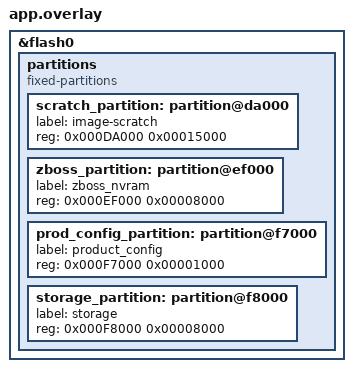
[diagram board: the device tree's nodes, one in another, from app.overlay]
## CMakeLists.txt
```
#
# Copyright (c) 2020 Nordic Semiconductor ASA
#
# SPDX-License-Identifier: LicenseRef-Nordic-5-Clause
#

cmake_minimum_required(VERSION 3.20.0)

find_package(Zephyr REQUIRED HINTS $ENV{ZEPHYR_BASE})

project("Light Switch")

# NORDIC SDK APP START
target_sources(app PRIVATE
  src/main.c
)

target_include_directories(app PRIVATE include)
# NORDIC SDK APP END

target_sources_ifdef(CONFIG_BT_NUS app PRIVATE
  src/nus_cmd.c
)
```

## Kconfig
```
#
# Copyright (c) 2020 Nordic Semiconductor ASA
#
# SPDX-License-Identifier: LicenseRef-Nordic-5-Clause
#

menu "Zephyr Kernel"
source "Kconfig.zephyr"
endmenu

module = NUS_CMD
module-str = NUS command
source "${ZEPHYR_BASE}/subsys/logging/Kconfig.template.log_config"


config LIGHT_SWITCH_CONFIGURE_TX_POWER
	bool "Configure TX power"
	default y
	help
		Enable this option to configure TX power for the sample.

config LIGHT_SWITCH_TX_POWER
	int "TX power"
	depends on LIGHT_SWITCH_CONFIGURE_TX_POWER
	default 0
	help
		TX power level in dBm.
```

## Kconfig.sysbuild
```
#
# Copyright (c) 2023 Nordic Semiconductor
#
# SPDX-License-Identifier: LicenseRef-Nordic-5-Clause
#

#### Radio core selection
config NRF_DEFAULT_IPC_RADIO
	default y

if BOOTLOADER_MCUBOOT

#### DFU multi-image support
config DFU_MULTI_IMAGE_PACKAGE_BUILD
	default y

config DFU_MULTI_IMAGE_PACKAGE_APP
	default y

#### DFU dual core configuration
if SOC_SERIES_NRF53X

config PM_EXTERNAL_FLASH_MCUBOOT_SECONDARY
	default y

config MCUBOOT_UPDATEABLE_IMAGES
	default 2

choice MCUBOOT_MODE
	default MCUBOOT_MODE_OVERWRITE_ONLY
endchoice

config SECURE_BOOT_NETCORE
	default y

config NETCORE_APP_UPDATE
	default y

config DFU_MULTI_IMAGE_PACKAGE_NET
	default y

endif # SOC_SERIES_NRF53X

endif # BOOTLOADER_MCUBOOT

source "share/sysbuild/Kconfig"
```

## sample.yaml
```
sample:
  description: Zigbee dimmable light switch based on ZBOSS stack
  name: Zigbee Light switch
tests:
  sample.zigbee.light_switch:
    sysbuild: true
    build_only: true
    integration_platforms:
      - nrf52840dk/nrf52840
      - nrf52833dk/nrf52833
      - nrf5340dk/nrf5340/cpuapp
      - nrf21540dk/nrf52840
    platform_allow:
      - nrf52840dk/nrf52840
      - nrf52833dk/nrf52833
      - nrf5340dk/nrf5340/cpuapp
      - nrf21540dk/nrf52840
    tags:
      - ci_build
      - smoke
      - sysbuild
      - ci_samples_zigbee
  sample.zigbee.light_switch.current_measurement:
    sysbuild: true
    build_only: true
    extra_args: CONFIG_SERIAL=n
    integration_platforms:
      - nrf52840dk/nrf52840
      - nrf52833dk/nrf52833
      - nrf5340dk/nrf5340/cpuapp
    platform_allow:
      - nrf52840dk/nrf52840
      - nrf52833dk/nrf52833
      - nrf5340dk/nrf5340/cpuapp
    tags:
      - ci_build
      - current_measurement
      - sysbuild
      - ci_samples_zigbee
  sample.zigbee.light_switch.fota:
    sysbuild: true
    build_only: true
    extra_args: >
      FILE_SUFFIX=fota
    integration_platforms:
      - nrf52840dk/nrf52840
      - nrf21540dk/nrf52840
    platform_allow:
      - nrf52840dk/nrf52840
      - nrf21540dk/nrf52840
    tags:
      - ci_build
      - smoke
      - sysbuild
      - ci_samples_zigbee
  sample.zigbee.light_switch.fota.nrf5340dk:
    sysbuild: true
    build_only: true
    extra_args: >
      FILE_SUFFIX=fota
    integration_platforms:
      - nrf5340dk/nrf5340/cpuapp
    platform_allow: nrf5340dk/nrf5340/cpuapp
    tags:
      - ci_build
      - smoke
      - sysbuild
      - ci_samples_zigbee
  sample.zigbee.light_switch.fota_and_multiprotocol:
    sysbuild: true
    build_only: true
    extra_args:
      - FILE_SUFFIX=fota
      - OVERLAY_CONFIG=overlay-multiprotocol_ble.conf
    integration_platforms:
      - nrf52840dk/nrf52840
    platform_allow: nrf52840dk/nrf52840
    tags:
      - ci_build
      - sysbuild
      - ci_samples_zigbee
  sample.zigbee.light_switch.fota_and_multiprotocol.nrf5340dk:
    sysbuild: true
    build_only: true
    extra_args:
      - FILE_SUFFIX=fota
      - OVERLAY_CONFIG=overlay-multiprotocol_ble.conf
    integration_platforms:
      - nrf5340dk/nrf5340/cpuapp
    platform_allow: nrf5340dk/nrf5340/cpuapp
    tags:
      - ci_build
      - sysbuild
      - ci_samples_zigbee
  sample.zigbee.light_switch.multiprotocol:
    sysbuild: true
    build_only: true
    extra_args: OVERLAY_CONFIG=overlay-multiprotocol_ble.conf
    integration_platforms:
      - nrf52840dk/nrf52840
      - nrf52833dk/nrf52833
      - nrf5340dk/nrf5340/cpuapp
    platform_allow:
      - nrf52840dk/nrf52840
      - nrf52833dk/nrf52833
      - nrf5340dk/nrf5340/cpuapp
    tags:
      - ci_build
      - sysbuild
      - ci_samples_zigbee
  sample.zigbee.light_switch.with_shell:
    sysbuild: true
    build_only: true
    extra_args:
      - CONFIG_ZIGBEE_SHELL=y
      - CONFIG_ZIGBEE_SHELL_DEBUG_CMD=y
      - CONFIG_ZIGBEE_LOGGER_EP=n
      - CONFIG_ZIGBEE_SHELL_ENDPOINT=1
      - CONFIG_LOG_MODE_DEFERRED=y
    integration_platforms:
      - nrf52840dk/nrf52840
      - nrf52833dk/nrf52833
      - nrf5340dk/nrf5340/cpuapp
      - nrf21540dk/nrf52840
    platform_allow:
      - nrf52840dk/nrf52840
      - nrf52833dk/nrf52833
      - nrf5340dk/nrf5340/cpuapp
      - nrf21540dk/nrf52840
    tags:
      - ci_build
      - shell
      - sysbuild
      - ci_samples_zigbee
```

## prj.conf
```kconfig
#
# Copyright (c) 2020 Nordic Semiconductor ASA
#
# SPDX-License-Identifier: LicenseRef-Nordic-5-Clause
#

CONFIG_NCS_SAMPLES_DEFAULTS=y

CONFIG_UART_INTERRUPT_DRIVEN=y
CONFIG_SERIAL=y
CONFIG_GPIO=y

# Make sure printk is not printing to the UART console
CONFIG_CONSOLE=y
CONFIG_UART_CONSOLE=y

CONFIG_HEAP_MEM_POOL_SIZE=2048

CONFIG_ZIGBEE=y
CONFIG_ZIGBEE_APP_UTILS=y
CONFIG_ZIGBEE_ROLE_END_DEVICE=y

# Enable DK LED and Buttons library
CONFIG_DK_LIBRARY=y

# This example requires more workqueue stack
CONFIG_SYSTEM_WORKQUEUE_STACK_SIZE=2048

# Enable API for powering down unused RAM parts
CONFIG_RAM_POWER_DOWN_LIBRARY=y

# Networking
CONFIG_NET_IPV6=n
CONFIG_NET_IP_ADDR_CHECK=n
CONFIG_NET_UDP=n
```

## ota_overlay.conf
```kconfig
#
# Copyright (c) 2020 Nordic Semiconductor ASA
#
# SPDX-License-Identifier: LicenseRef-BSD-5-Clause-Nordic
#

CONFIG_ZIGBEE_FOTA=y
CONFIG_ZIGBEE_FOTA_HW_VERSION=52
CONFIG_ZIGBEE_FOTA_ENDPOINT=5
CONFIG_MCUBOOT_IMAGE_VERSION="1.2.3"
CONFIG_ZIGBEE_FOTA_COMMENT="light_switch"

# Ensure an MCUboot-compatible binary is generated.
CONFIG_IMG_MANAGER=y
CONFIG_DFU_TARGET_MCUBOOT=y
CONFIG_IMG_ERASE_PROGRESSIVELY=y
CONFIG_ZIGBEE_FOTA_PROGRESS_EVT=y
```

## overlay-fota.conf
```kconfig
#
# Copyright (c) 2020 Nordic Semiconductor ASA
#
# SPDX-License-Identifier: LicenseRef-Nordic-5-Clause
#

CONFIG_ZIGBEE_FOTA=y
CONFIG_ZIGBEE_FOTA_HW_VERSION=52
CONFIG_ZIGBEE_FOTA_ENDPOINT=5
CONFIG_MCUBOOT_IMAGE_VERSION="1.2.3"
CONFIG_ZIGBEE_FOTA_COMMENT="light_switch"

# Ensure an MCUboot-compatible binary is generated.
CONFIG_IMG_MANAGER=y
CONFIG_DFU_TARGET_MCUBOOT=y
CONFIG_IMG_ERASE_PROGRESSIVELY=y
CONFIG_ZIGBEE_FOTA_PROGRESS_EVT=y

# Increase the number of RX buffers
CONFIG_NRF_802154_RX_BUFFERS=32
```

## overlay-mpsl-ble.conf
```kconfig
# Enable NUS command service
CONFIG_NUS_CMD=y

# BLE configuration
CONFIG_BT_DEVICE_NAME="Zigbee_Switch"
CONFIG_BT_DEVICE_APPEARANCE=833
CONFIG_BT_MAX_CONN=1
CONFIG_BT_MAX_PAIRED=1
CONFIG_BT_PHY_UPDATE=n

# Enable multiprotocol
CONFIG_BT_LL_NRFXLIB_DEFAULT=y

# BLE uses ECB peripheral directly
CONFIG_CRYPTO=n
CONFIG_CRYPTO_NRF_ECB=n
```

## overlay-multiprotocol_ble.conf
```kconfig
#
# Copyright (c) 2020 Nordic Semiconductor ASA
#
# SPDX-License-Identifier: LicenseRef-Nordic-5-Clause
#

# BLE configuration
CONFIG_BT=y
CONFIG_BT_SMP=y
CONFIG_BT_PERIPHERAL=y
CONFIG_BT_DEVICE_NAME="Zigbee_Switch"
CONFIG_BT_DEVICE_APPEARANCE=833
CONFIG_BT_MAX_CONN=1
CONFIG_BT_MAX_PAIRED=1
CONFIG_BT_PHY_UPDATE=n

# Enable the NUS service
CONFIG_BT_NUS=y

# Enable bonding
CONFIG_SETTINGS=y
CONFIG_BT_SETTINGS=y

# BLE uses ECB peripheral directly
CONFIG_CRYPTO=n
CONFIG_CRYPTO_NRF_ECB=n
```

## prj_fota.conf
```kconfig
#
# Copyright (c) 2020 Nordic Semiconductor ASA
#
# SPDX-License-Identifier: LicenseRef-Nordic-5-Clause
#

CONFIG_NCS_SAMPLES_DEFAULTS=y

CONFIG_UART_INTERRUPT_DRIVEN=y
CONFIG_SERIAL=y
CONFIG_GPIO=y

# Make sure printk is not printing to the UART console
CONFIG_CONSOLE=y
CONFIG_UART_CONSOLE=y

CONFIG_HEAP_MEM_POOL_SIZE=2048

CONFIG_ZIGBEE=y
CONFIG_ZIGBEE_APP_UTILS=y
CONFIG_ZIGBEE_ROLE_END_DEVICE=y

# Enable DK LED and Buttons library
CONFIG_DK_LIBRARY=y

# This example requires more workqueue stack
CONFIG_SYSTEM_WORKQUEUE_STACK_SIZE=2048

# Enable API for powering down unused RAM parts
CONFIG_RAM_POWER_DOWN_LIBRARY=y

# Networking
CONFIG_NET_IPV6=n
CONFIG_NET_IP_ADDR_CHECK=n
CONFIG_NET_UDP=n


#######################
# Zigbee FOTA overlay #
#######################

# Enable Zigbee FOTA library
CONFIG_ZIGBEE_FOTA=y
CONFIG_ZIGBEE_FOTA_HW_VERSION=52
CONFIG_ZIGBEE_FOTA_ENDPOINT=5
CONFIG_MCUBOOT_IMGTOOL_SIGN_VERSION="1.2.3"
CONFIG_ZIGBEE_FOTA_COMMENT="light_switch"

# Ensure an MCUboot-compatible binary is generated.
CONFIG_IMG_MANAGER=y
CONFIG_STREAM_FLASH=y
CONFIG_DFU_TARGET_MCUBOOT=y
CONFIG_IMG_ERASE_PROGRESSIVELY=y
CONFIG_ZIGBEE_FOTA_PROGRESS_EVT=y

# Increase the number of RX buffers
CONFIG_NRF_802154_RX_BUFFERS=32
```

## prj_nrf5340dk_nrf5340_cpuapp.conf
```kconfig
#
# Copyright (c) 2020 Nordic Semiconductor ASA
#
# SPDX-License-Identifier: LicenseRef-Nordic-5-Clause
#

CONFIG_NCS_SAMPLES_DEFAULTS=y

CONFIG_UART_INTERRUPT_DRIVEN=y
CONFIG_SERIAL=y
CONFIG_GPIO=y

# Make sure printk is not printing to the UART console
CONFIG_CONSOLE=y
CONFIG_UART_CONSOLE=y

CONFIG_HEAP_MEM_POOL_SIZE=2048
CONFIG_MAIN_STACK_SIZE=2048

CONFIG_ZIGBEE=y
CONFIG_ZIGBEE_APP_UTILS=y
CONFIG_ZIGBEE_ROLE_END_DEVICE=y

# Enable DK LED and Buttons library
CONFIG_DK_LIBRARY=y

# This example requires more workqueue stack
CONFIG_SYSTEM_WORKQUEUE_STACK_SIZE=2048

# Use software cryptography on nRF5340
CONFIG_CTR_DRBG_CSPRNG_GENERATOR=y
CONFIG_ZIGBEE_USE_SOFTWARE_AES=y

# Enable API for powering down unused RAM parts
CONFIG_RAM_POWER_DOWN_LIBRARY=y

#Networking
CONFIG_MPSL=n
CONFIG_NET_IPV6_MLD=n
CONFIG_NET_IPV6_NBR_CACHE=n
CONFIG_NET_IPV6_RA_RDNSS=n
CONFIG_NET_IP_ADDR_CHECK=n
CONFIG_NET_UDP=n
```

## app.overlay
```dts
/* Copyright (c) 2020 Nordic Semiconductor ASA
 *
 * SPDX-License-Identifier: Apache-2.0
 */

/delete-node/ &scratch_partition;
/delete-node/ &storage_partition;

&flash0 {
	partitions {
		compatible = "fixed-partitions";
		#address-cells = <1>;
		#size-cells = <1>;

		scratch_partition: partition@da000 {
			label = "image-scratch";
			reg = <0x000DA000 0x00015000>;
		};
		zboss_partition: partition@ef000 {
			label = "zboss_nvram";
			reg = <0x000EF000 0x00008000>;
		};
		prod_config_partition: partition@f7000 {
			label = "product_config";
			reg = <0x000F7000 0x00001000>;
		};
		storage_partition: partition@f8000 {
			label = "storage";
			reg = <0x000F8000 0x00008000>;
		};
	};
};
```

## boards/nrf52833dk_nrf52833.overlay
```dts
/*
 * Copyright (c) 2020 Nordic Semiconductor ASA
 *
 * SPDX-License-Identifier: LicenseRef-BSD-5-Clause-Nordic
 */

/ {
	chosen {
		zephyr,entropy = &rng;
	};
};
```

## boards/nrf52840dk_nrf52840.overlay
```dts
/*
 * Copyright (c) 2023 Nordic Semiconductor ASA
 *
 * SPDX-License-Identifier: LicenseRef-Nordic-5-Clause
 */
/ {
	chosen {
		ncs,zigbee-timer = &timer2;
	};
};

&timer2 {
	status = "okay";
};
```

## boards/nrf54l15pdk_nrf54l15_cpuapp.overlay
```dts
/* SPDX-License-Identifier: Apache-2.0 */

/ {
	chosen {
        zephyr,entropy = &prng;
		ncs,zigbee-uart = &uart30;
		ncs,zboss-trace-uart = &uart30;
	};
};

&prng {
	status = "okay";
};
```

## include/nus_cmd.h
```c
/*
 * Copyright (c) 2020 Nordic Semiconductor ASA
 *
 * SPDX-License-Identifier: LicenseRef-Nordic-5-Clause
 */

/**
 * @file nus_cmd.h
 *
 * @brief APIs for NUS Command Service.
 */

#ifndef __NUS_CMD_H__
#define __NUS_CMD_H__

/** @brief Type indicates function called when Bluetooth LE connection
 *         is established.
 *
 * @param[in] item pointer to work item.
 */
typedef void (*nus_connection_cb_t)(struct k_work *item);

/** @brief Type indicates function called when Bluetooth LE connection is ended.
 *
 * @param[in] item pointer to work item.
 */
typedef void (*nus_disconnection_cb_t)(struct k_work *item);

/** @brief NUS command entry.
 */
struct nus_entry {
	const char *cmd;        /**< Command string. */
	struct k_work work;     /**< Command work item. */
};

/**@brief Macro to initialise (bind) command string to work handler.
 */
#define NUS_COMMAND(_cmd, _handler)		      \
	{					      \
		.work = Z_WORK_INITIALIZER(_handler), \
		.cmd = _cmd,			      \
	}					      \

/**@brief Function to initialise NUS Command service.
 *
 * @param[in] on_connect Callback that will be called when central connects to
 *			 the NUS service.
 * @param[in] on_disconnect Callback that will be called when BLE central
 *			    disconnects from the NUS service.
 * @param[in] command_set   A pointer to an array with NUS commands.
 */
void nus_cmd_init(nus_connection_cb_t on_connect,
		  nus_disconnection_cb_t on_disconnect,
		  struct nus_entry *command_set);

#endif
```

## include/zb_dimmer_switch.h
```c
/*
 * Copyright (c) 2022 Nordic Semiconductor ASA
 *
 * SPDX-License-Identifier: LicenseRef-Nordic-5-Clause
 */

#ifndef ZB_DIMMER_SWITCH_H
#define ZB_DIMMER_SWITCH_H 1

/**
 *  @defgroup ZB_DEFINE_DEVICE_DIMMER_SWITCH Dimmer Switch
 *  @{
 *  @details
 *      - @ref ZB_ZCL_BASIC \n
 *      - @ref ZB_ZCL_IDENTIFY \n
 *      - @ref ZB_ZCL_SCENES \n
 *      - @ref ZB_ZCL_GROUPS \n
 *      - @ref ZB_ZCL_ON_OFF \n
 *      - @ref ZB_ZCL_LEVEL_CONTROL
 */

/** Dimmer Switch Device ID */
#define ZB_DIMMER_SWITCH_DEVICE_ID 0x0104

/** Dimmer Switch device version */
#define ZB_DEVICE_VER_DIMMER_SWITCH 0

/** @cond internals_doc */

/** Dimmer Switch IN (server) clusters number */
#define ZB_DIMMER_SWITCH_IN_CLUSTER_NUM 2

/** Dimmer Switch OUT (client) clusters number */
#define ZB_DIMMER_SWITCH_OUT_CLUSTER_NUM 5

/** Dimmer switch total (IN+OUT) cluster number */
#define ZB_DIMMER_SWITCH_CLUSTER_NUM \
	(ZB_DIMMER_SWITCH_IN_CLUSTER_NUM + ZB_DIMMER_SWITCH_OUT_CLUSTER_NUM)

/** Number of attribute for reporting on Dimmer Switch device */
#define ZB_DIMMER_SWITCH_REPORT_ATTR_COUNT 0

/** @endcond */ /* internals_doc */

/**
 * @brief Declare cluster list for Dimmer Switch device
 * @param cluster_list_name - cluster list variable name
 * @param basic_server_attr_list - attribute list for Basic cluster (server role)
 * @param identify_client_attr_list - attribute list for Identify cluster (client role)
 * @param identify_server_attr_list - attribute list for Identify cluster (server role)
 * @param scenes_client_attr_list - attribute list for Scenes cluster (client role)
 * @param groups_client_attr_list - attribute list for Groups cluster (client role)
 * @param on_off_client_attr_list - attribute list for On/Off cluster (client role)
 * @param level_control_client_attr_list - attribute list for Level Control cluster (client role)
 */
#define ZB_DECLARE_DIMMER_SWITCH_CLUSTER_LIST(					  \
		cluster_list_name,						  \
		basic_server_attr_list,						  \
		identify_client_attr_list,					  \
		identify_server_attr_list,					  \
		scenes_client_attr_list,					  \
		groups_client_attr_list,					  \
		on_off_client_attr_list,					  \
		level_control_client_attr_list)					  \
zb_zcl_cluster_desc_t cluster_list_name[] =					  \
{										  \
	ZB_ZCL_CLUSTER_DESC(							  \
		ZB_ZCL_CLUSTER_ID_BASIC,					  \
		ZB_ZCL_ARRAY_SIZE(basic_server_attr_list, zb_zcl_attr_t),	  \
		(basic_server_attr_list),					  \
		ZB_ZCL_CLUSTER_SERVER_ROLE,					  \
		ZB_ZCL_MANUF_CODE_INVALID					  \
	),									  \
	ZB_ZCL_CLUSTER_DESC(							  \
		ZB_ZCL_CLUSTER_ID_IDENTIFY,					  \
		ZB_ZCL_ARRAY_SIZE(identify_server_attr_list, zb_zcl_attr_t),	  \
		(identify_server_attr_list),					  \
		ZB_ZCL_CLUSTER_SERVER_ROLE,					  \
		ZB_ZCL_MANUF_CODE_INVALID					  \
	),									  \
	ZB_ZCL_CLUSTER_DESC(							  \
		ZB_ZCL_CLUSTER_ID_IDENTIFY,					  \
		ZB_ZCL_ARRAY_SIZE(identify_client_attr_list, zb_zcl_attr_t),	  \
		(identify_client_attr_list),					  \
		ZB_ZCL_CLUSTER_CLIENT_ROLE,					  \
		ZB_ZCL_MANUF_CODE_INVALID					  \
	),									  \
	ZB_ZCL_CLUSTER_DESC(							  \
		ZB_ZCL_CLUSTER_ID_SCENES,					  \
		ZB_ZCL_ARRAY_SIZE(scenes_client_attr_list, zb_zcl_attr_t),	  \
		(scenes_client_attr_list),					  \
		ZB_ZCL_CLUSTER_CLIENT_ROLE,					  \
		ZB_ZCL_MANUF_CODE_INVALID					  \
	),									  \
	ZB_ZCL_CLUSTER_DESC(							  \
		ZB_ZCL_CLUSTER_ID_GROUPS,					  \
		ZB_ZCL_ARRAY_SIZE(groups_client_attr_list, zb_zcl_attr_t),	  \
		(groups_client_attr_list),					  \
		ZB_ZCL_CLUSTER_CLIENT_ROLE,					  \
		ZB_ZCL_MANUF_CODE_INVALID					  \
	),									  \
	ZB_ZCL_CLUSTER_DESC(							  \
		ZB_ZCL_CLUSTER_ID_ON_OFF,					  \
		ZB_ZCL_ARRAY_SIZE(on_off_client_attr_list, zb_zcl_attr_t),	  \
		(on_off_client_attr_list),					  \
		ZB_ZCL_CLUSTER_CLIENT_ROLE,					  \
		ZB_ZCL_MANUF_CODE_INVALID					  \
	),									  \
	ZB_ZCL_CLUSTER_DESC(							  \
		ZB_ZCL_CLUSTER_ID_LEVEL_CONTROL,				  \
		ZB_ZCL_ARRAY_SIZE(level_control_client_attr_list, zb_zcl_attr_t), \
		(level_control_client_attr_list),				  \
		ZB_ZCL_CLUSTER_CLIENT_ROLE,					  \
		ZB_ZCL_MANUF_CODE_INVALID					  \
	)									  \
}


/** @cond internals_doc */
/**
 * @brief Declare simple descriptor for Dimmer switch device
 * @param ep_name - endpoint variable name
 * @param ep_id - endpoint ID
 * @param in_clust_num - number of supported input clusters
 * @param out_clust_num - number of supported output clusters
 */
#define ZB_ZCL_DECLARE_DIMMER_SWITCH_SIMPLE_DESC(				    \
	ep_name, ep_id, in_clust_num, out_clust_num)				    \
	ZB_DECLARE_SIMPLE_DESC(in_clust_num, out_clust_num);			    \
	ZB_AF_SIMPLE_DESC_TYPE(in_clust_num, out_clust_num) simple_desc_##ep_name = \
	{									    \
		ep_id,								    \
		ZB_AF_HA_PROFILE_ID,						    \
		ZB_DIMMER_SWITCH_DEVICE_ID,					    \
		ZB_DEVICE_VER_DIMMER_SWITCH,					    \
		0,								    \
		in_clust_num,							    \
		out_clust_num,							    \
		{								    \
			ZB_ZCL_CLUSTER_ID_BASIC,				    \
			ZB_ZCL_CLUSTER_ID_IDENTIFY,				    \
			ZB_ZCL_CLUSTER_ID_IDENTIFY,				    \
			ZB_ZCL_CLUSTER_ID_SCENES,				    \
			ZB_ZCL_CLUSTER_ID_GROUPS,				    \
			ZB_ZCL_CLUSTER_ID_ON_OFF,				    \
			ZB_ZCL_CLUSTER_ID_LEVEL_CONTROL,			    \
		}								    \
	}

/** @endcond */ /* internals_doc */

/**
 * @brief Declare endpoint for Dimmer Switch device
 * @param ep_name - endpoint variable name
 * @param ep_id - endpoint ID
 * @param cluster_list - endpoint cluster list
 */
#define ZB_DECLARE_DIMMER_SWITCH_EP(ep_name, ep_id, cluster_list)		      \
	ZB_ZCL_DECLARE_DIMMER_SWITCH_SIMPLE_DESC(ep_name, ep_id,		      \
		  ZB_DIMMER_SWITCH_IN_CLUSTER_NUM, ZB_DIMMER_SWITCH_OUT_CLUSTER_NUM); \
										      \
	ZB_AF_DECLARE_ENDPOINT_DESC(ep_name, ep_id, ZB_AF_HA_PROFILE_ID, 0, NULL,     \
		ZB_ZCL_ARRAY_SIZE(cluster_list, zb_zcl_cluster_desc_t), cluster_list, \
		(zb_af_simple_desc_1_1_t *)&simple_desc_##ep_name,		      \
		0, NULL, /* No reporting ctx */					      \
		0, NULL) /* No CVC ctx */

/** @} */

#endif /* ZB_DIMMER_SWITCH_H */
```

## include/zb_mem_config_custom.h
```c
/*
 * Copyright (c) 2020 Nordic Semiconductor ASA
 *
 * SPDX-License-Identifier: LicenseRef-Nordic-5-Clause
 */

#ifndef ZB_MEM_CONFIG_CUSTOM_H
#define ZB_MEM_CONFIG_CUSTOM_H 1


#define ZB_CONFIG_ROLE_ZED
#define ZB_CONFIG_OVERALL_NETWORK_SIZE 16

/**
 * Light routing and application traffic from/to that device.
 */
#define ZB_CONFIG_LIGHT_TRAFFIC

/**
 * Simple user's application at that device: not too many relations
 * to other devices.
 */
#define ZB_CONFIG_APPLICATION_SIMPLE

/**
 * The below section is for advanced users.
 * Before modifying any values, please make sure you fully understand the
 * impact, for example by reading zb_mem_config_common.h
 */
#include "zb_mem_config_common.h"

/**
 * Now if you REALLY know what you do, you can study zb_mem_config_common.h
 * and redefine some configuration parameters, like:
 */
#if defined(CONFIG_LIGHT_SWITCH_CONFIGURE_TX_POWER) && \
	defined(CONFIG_ZIGBEE_CHANNEL_SELECTION_MODE_MULTI)
#undef ZB_CONFIG_SCHEDULER_Q_SIZE
#define ZB_CONFIG_SCHEDULER_Q_SIZE 28
#undef ZB_CONFIG_IOBUF_POOL_SIZE
#define ZB_CONFIG_IOBUF_POOL_SIZE 42
#else
#undef ZB_CONFIG_SCHEDULER_Q_SIZE
#define ZB_CONFIG_SCHEDULER_Q_SIZE 24
#endif /* CONFIG_LIGHT_SWITCH_CONFIGURE_TX_POWER && CONFIG_ZIGBEE_CHANNEL_SELECTION_MODE_MULTI */

/**
 * Increase OTA transfer time by extending the APS duplicate rejection table.
 * This value must be less than the amount of possible APS counter values (256).
 */
#undef ZB_CONFIG_APS_DUPS_TABLE_SIZE
#define ZB_CONFIG_APS_DUPS_TABLE_SIZE 64

/* Memory context definitions. */
#include "zb_mem_config_context.h"

#endif /* ZB_MEM_CONFIG_CUSTOM_H */
```

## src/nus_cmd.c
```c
/*
 * Copyright (c) 2020 Nordic Semiconductor ASA
 *
 * SPDX-License-Identifier: LicenseRef-Nordic-5-Clause
 */
#include <zephyr/kernel.h>
#include <zephyr/bluetooth/gatt.h>
#include <zephyr/bluetooth/hci.h>
#include <zephyr/bluetooth/uuid.h>
#include <bluetooth/services/nus.h>
#include <zephyr/logging/log.h>
#include <zephyr/settings/settings.h>

#include "nus_cmd.h"

LOG_MODULE_REGISTER(nus_cmd, CONFIG_NUS_CMD_LOG_LEVEL);

#define DEVICE_NAME        CONFIG_BT_DEVICE_NAME
#define DEVICE_NAME_LEN    (sizeof(DEVICE_NAME) - 1)

static void connected(struct bt_conn *conn, uint8_t err);
static void disconnected(struct bt_conn *conn, uint8_t reason);
static void auth_passkey_display(struct bt_conn *conn, unsigned int passkey);
static void auth_cancel(struct bt_conn *conn);
static void pairing_complete(struct bt_conn *conn, bool bonded);
static void pairing_failed(struct bt_conn *conn, enum bt_security_err reason);
static void __attribute__((unused))
security_changed(struct bt_conn *conn, bt_security_t level,
		 enum bt_security_err err);

static struct bt_conn_auth_cb conn_auth_callbacks = {
	.passkey_display = auth_passkey_display,
	.cancel = auth_cancel,
};

static struct bt_conn_auth_info_cb conn_auth_info_callbacks = {
	.pairing_complete = pairing_complete,
	.pairing_failed = pairing_failed
};

static struct bt_conn_cb conn_callbacks = {
	.connected = connected,
	.disconnected = disconnected,
	COND_CODE_1(CONFIG_BT_SMP, (.security_changed = security_changed), ())
};

static const struct bt_data ad[] = {
	BT_DATA_BYTES(BT_DATA_FLAGS, (BT_LE_AD_GENERAL | BT_LE_AD_NO_BREDR)),
	BT_DATA(BT_DATA_NAME_COMPLETE, DEVICE_NAME, DEVICE_NAME_LEN),
};

static const struct bt_data sd[] = {
	BT_DATA_BYTES(BT_DATA_UUID128_ALL, BT_UUID_NUS_VAL),
};

static struct k_work on_connect_work;
static struct k_work on_disconnect_work;
static struct bt_conn *current_conn;
static struct nus_entry *nus_commands;

static void connected(struct bt_conn *conn, uint8_t err)
{
	if (err) {
		LOG_ERR("Connection failed (err %u)", err);
		return;
	}

	LOG_INF("Connected");
	current_conn = bt_conn_ref(conn);

	k_work_submit(&on_connect_work);
}

static void disconnected(struct bt_conn *conn, uint8_t reason)
{
	LOG_INF("Disconnected (reason %u)", reason);

	if (current_conn) {
		bt_conn_unref(current_conn);
		current_conn = NULL;

		k_work_submit(&on_disconnect_work);
	}
}

static char *ble_addr(struct bt_conn *conn)
{
	static char addr[BT_ADDR_LE_STR_LEN];

	bt_addr_le_to_str(bt_conn_get_dst(conn), addr, sizeof(addr));

	return addr;
}

static void __attribute__((unused))
security_changed(struct bt_conn *conn, bt_security_t level,
		 enum bt_security_err err)
{
	char *addr = ble_addr(conn);

	if (!err) {
		LOG_INF("Security changed: %s level %u", addr, level);
	} else {
		LOG_INF("Security failed: %s level %u err %d", addr,
			level, err);
	}
}

static void auth_passkey_display(struct bt_conn *conn, unsigned int passkey)
{
	char *addr = ble_addr(conn);

	LOG_INF("Passkey for %s: %06u", addr, passkey);
}

static void auth_cancel(struct bt_conn *conn)
{
	char *addr = ble_addr(conn);

	LOG_INF("Pairing cancelled: %s", addr);
}

static void pairing_complete(struct bt_conn *conn, bool bonded)
{
	char *addr = ble_addr(conn);

	LOG_INF("Pairing completed: %s, bonded: %d", addr, bonded);
}

static void pairing_failed(struct bt_conn *conn, enum bt_security_err reason)
{
	char *addr = ble_addr(conn);

	LOG_INF("Pairing failed conn: %s, reason %d", addr, reason);
}

static int ble_utils_init(struct bt_nus_cb *nus_clbs,
			  nus_connection_cb_t on_connect,
			  nus_disconnection_cb_t on_disconnect)
{
	int ret;

	k_work_init(&on_connect_work, on_connect);
	k_work_init(&on_disconnect_work, on_disconnect);

	bt_conn_cb_register(&conn_callbacks);

	if (IS_ENABLED(CONFIG_BT_SMP)) {
		ret = bt_conn_auth_cb_register(&conn_auth_callbacks);
		if (ret) {
			LOG_ERR("Failed to register authorization callbacks.");
			goto end;
		}

		ret = bt_conn_auth_info_cb_register(&conn_auth_info_callbacks);
		if (ret) {
			LOG_ERR("Failed to register authorization info callbacks.");
			goto end;
		}
	}

	ret = bt_enable(NULL);
	if (ret) {
		LOG_ERR("Bluetooth initialization failed (error: %d)", ret);
		goto end;
	}

	LOG_INF("Bluetooth initialized");

	if (IS_ENABLED(CONFIG_SETTINGS)) {
		settings_load();
	}

	ret = bt_nus_init(nus_clbs);
	if (ret) {
		LOG_ERR("Failed to initialize UART service (error: %d)", ret);
		goto end;
	}

	ret = bt_le_adv_start(BT_LE_ADV_CONN_FAST_2, ad, ARRAY_SIZE(ad), sd,
			      ARRAY_SIZE(sd));
	if (ret) {
		LOG_ERR("Advertising failed to start (error: %d)", ret);
		goto end;
	}

end:
	return ret;
}

static void nus_command_handler(struct bt_conn *conn,
				const uint8_t *const data, uint16_t length)
{
	LOG_HEXDUMP_DBG(data, length, "NUS recv:");

	for (struct nus_entry *p = nus_commands; p->cmd != NULL; p++) {
		if ((length >= strlen(p->cmd)) &&
		    (!strncmp(p->cmd, (const char *)data, strlen(p->cmd)))) {
			LOG_DBG("Matched cmd: %s", p->cmd);
			k_work_submit(&p->work);
			return;
		}
	}

	LOG_HEXDUMP_WRN(data, length, "Command unrecognized");
}

void nus_cmd_init(nus_connection_cb_t on_connect,
		  nus_disconnection_cb_t on_disconnect,
		  struct nus_entry *command_set)
{
	struct bt_nus_cb nus_clbs = {
		.received = nus_command_handler,
		.sent = NULL,
	};

	nus_commands = command_set;
	ble_utils_init(&nus_clbs, on_connect, on_disconnect);
}
```
